# future_system_map: IP-XACT component
VLNV example.vendor:example_lib:future_system_map:1.0
Example system map with three unique register blocks and composite block

## Address spaces and blocks
main_map.BlockA_1: base 0x0000, range 0x100, width 32, register
main_map.BlockB_1: base 0x1000, range 0x100, width 32, register
main_map.BlockC_1: base 0x2000, range 0x200, width 32, register
main_map.BlockA_2: base 0x3000, range 0x100, width 32, register

## Registers
Registers are 32-bit, access per field, no defined reset value unless marked. A register's access mark holds for its fields unless they carry their own. Offsets are from the block's base; lines under a group give offsets from that group; [hi:lo] are bit positions; {n}, {i} and the like mark numbered series; 'fields as' and 'values as' point back to an identical list; <NAME> marks a mode.

## main_map.BlockA_1
Base 0x00000000
Same registers: main_map.BlockA_2 0x00003000
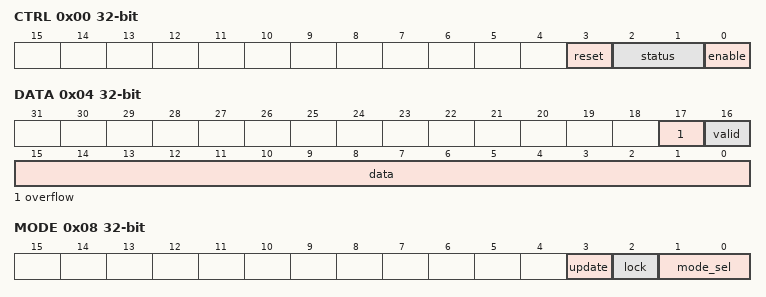
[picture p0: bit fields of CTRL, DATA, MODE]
0x00 CTRL
  [3] reset wo, [2:1] status ro, [0] enable rw
0x04 DATA
  [17] overflow rw, [16] valid ro, [15:0] data wo
0x08 MODE
  [3] update wo, [2] lock ro, [1:0] mode_sel rw

## main_map.BlockB_1
Base 0x00001000
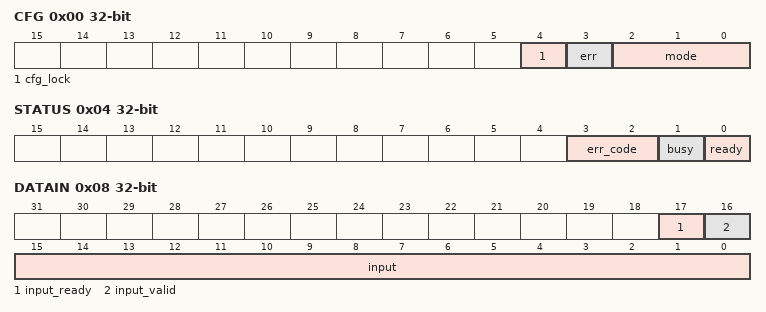
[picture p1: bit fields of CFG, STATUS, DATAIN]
0x00 CFG
  [4] cfg_lock wo, [3] err ro, [2:0] mode rw
0x04 STATUS
  [3:2] err_code wo, [1] busy rw, [0] ready ro
0x08 DATAIN
  [17] input_ready rw, [16] input_valid ro, [15:0] input wo
